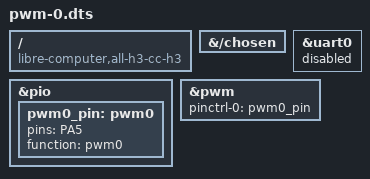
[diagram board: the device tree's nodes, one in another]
// SPDX-License-Identifier: (GPL-2.0-or-later OR MIT)
/*
 * Copyright (c) 2023 Da Xue <da@libre.computer>
 * Author: Da Xue <da@libre.computer>
 */
/*
 * Summary: PWM0 on the 3-pin debug UART header 2J3 pin 3 (PA5); takes the
 * pin from UART0, so the serial console is disabled
 *
 * Pins (Header.Pin  Name  Pad  Ref — cross-ref gpio.map):
 *   2J3.3    PA5           H6      CPUX-RX
 */
/dts-v1/;
/plugin/;

/ {
	compatible = "libre-computer,all-h3-cc-h3",
		"libretech,all-h3-cc-h3",
		"libre-computer,all-h3-cc-h5",
		"libretech,all-h3-cc-h5",
		"allwinner,sun8i-h3",
		"allwinner,sun50i-h5";

	fragment@0 {
		target-path = "/chosen";
		__overlay__ {
			/delete-property/ stdout-path;
		};
	};

	fragment@1 {
		target = <&uart0>;
		__overlay__ {
			status = "disabled";
		};
	};

	fragment@2 {
		target = <&pio>;
		__overlay__ {
			pwm0_pin: pwm0 {
				pins = "PA5";
				function = "pwm0";
			};
		};
	};

	fragment@3 {
		target = <&pwm>;
		__overlay__ {
			pinctrl-names = "default";
			pinctrl-0 = <&pwm0_pin>;
			status = "okay";
		};
	};
};
